# STM32H573 register map
File version: 0.4
CPU: CM33 r0p0, little endian, MPU, FPU, 4 interrupt priority bits
Registers are 32-bit, read-write, reset 0x0 unless marked. A register's access mark holds for its fields unless they carry their own. Offsets are from the block's base; [hi:lo] are bit positions; {n}, {i} and the like mark numbered series.

## TIM15 — TIM15 address block description
Base 0x40014000
Same registers: SEC_TIM15 0x50014000
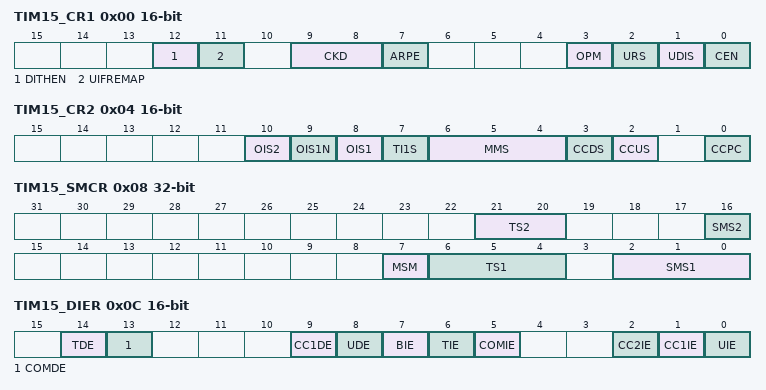
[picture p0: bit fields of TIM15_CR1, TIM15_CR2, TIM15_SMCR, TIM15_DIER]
0x00 TIM15_CR1 16-bit — TIM15 control register 1
  [12] DITHEN — Dithering enable Note: The DITHEN bit can only be modified when CEN bit is reset.
  [11] UIFREMAP — UIF status bit remapping
  [9:8] CKD — Clock division This bitfield indicates the division ratio between the timer clock (tim_ker_ck) frequency and the dead-time and sampling clock (tDTS) used by the dead-time generators and the digital filters (tim_tix)
  [7] ARPE — Auto-reload preload enable
  [3] OPM — One-pulse mode
  [2] URS — Update request source This bit is set and cleared by software to select the UEV event sources. Counter overflow/underflow Setting the UG bit Update generation through the slave mode controller
  [1] UDIS — Update disable This bit is set and cleared by software to enable/disable UEV event generation. Counter overflow/underflow Setting the UG bit Update generation through the slave mode controller Buffered registers are then loaded with their preload values.
  [0] CEN — Counter enable Note: External clock and gated mode can work only if the CEN bit has been previously set by software. However trigger mode can set the CEN bit automatically by hardware.
0x04 TIM15_CR2 16-bit — TIM15 control register 2
  [10] OIS2 — Output idle state 2 (tim_oc2 output) Note: This bit cannot be modified as long as LOCK level 1, 2 or 3 has been programmed (LOCK bits in the TIM15_BKR register).
  [9] OIS1N — Output Idle state 1 (tim_oc1n output) Note: This bit can not be modified as long as LOCK level 1, 2 or 3 has been programmed (LOCK bits in TIM15_BKR register).
  [8] OIS1 — Output Idle state 1 (tim_oc1 output) Note: This bit can not be modified as long as LOCK level 1, 2 or 3 has been programmed (LOCK bits in TIM15_BKR register).
  [7] TI1S — tim_ti1 selection
  [6:4] MMS — Master mode selection These bits allow to select the information to be sent in master mode to slave timers for synchronization (tim_trgo). The combination is as follows:
  [3] CCDS — Capture/compare DMA selection
  [2] CCUS — Capture/compare control update selection Note: This bit acts only on channels that have a complementary output.
  [0] CCPC — Capture/compare preloaded control Note: This bit acts only on channels that have a complementary output.
0x08 TIM15_SMCR — TIM15 slave mode control register
  [21:20] TS2 — Trigger selection This bit field selects the trigger input to be used to synchronize the counter. Others: Reserved See for more details on tim_itrx meaning for each timer. Note: These bits must be changed only when they are not used (e.g. when SMS=000) to avoid wrong edge detections at the transition.
  [16] SMS2 — Slave mode selection When external signals are selected the active edge of the trigger signal (tim_trgi) is linked to the polarity selected on the external input (see Input Control register and Control Register description. Others: Reserved. Note: The gated mode must not be used if tim_ti1f_ed is selected as the trigger input (TS=’00100’). Indeed, tim_ti1f_ed outputs 1 pulse for each transition on tim_ti1f, whereas the gated mode checks the level of the trigger signal. Note: The clock of the slave peripherals (timer, ADC, ...) receiving the tim_trgo signal must be enabled prior to receive events from the master timer, and the clock frequency (prescaler) must not be changed on-the-fly while triggers are received from the master timer.
  [7] MSM — Master/slave mode
  [6:4] TS1 — Trigger selection This bit field selects the trigger input to be used to synchronize the counter. Others: Reserved See for more details on tim_itrx meaning for each timer. Note: These bits must be changed only when they are not used (e.g. when SMS=000) to avoid wrong edge detections at the transition.
  [2:0] SMS1 — Slave mode selection When external signals are selected the active edge of the trigger signal (tim_trgi) is linked to the polarity selected on the external input (see Input Control register and Control Register description. Others: Reserved. Note: The gated mode must not be used if tim_ti1f_ed is selected as the trigger input (TS=’00100’). Indeed, tim_ti1f_ed outputs 1 pulse for each transition on tim_ti1f, whereas the gated mode checks the level of the trigger signal. Note: The clock of the slave peripherals (timer, ADC, ...) receiving the tim_trgo signal must be enabled prior to receive events from the master timer, and the clock frequency (prescaler) must not be changed on-the-fly while triggers are received from the master timer.
0x0C TIM15_DIER 16-bit — TIM15 DMA/interrupt enable register
  [14] TDE — Trigger DMA request enable
  [13] COMDE — COM DMA request enable
  [9] CC1DE — Capture/Compare 1 DMA request enable
  [8] UDE — Update DMA request enable
  [7] BIE — Break interrupt enable
  [6] TIE — Trigger interrupt enable
  [5] COMIE — COM interrupt enable
  [2] CC2IE — Capture/Compare 2 interrupt enable
  [1] CC1IE — Capture/Compare 1 interrupt enable
  [0] UIE — Update interrupt enable
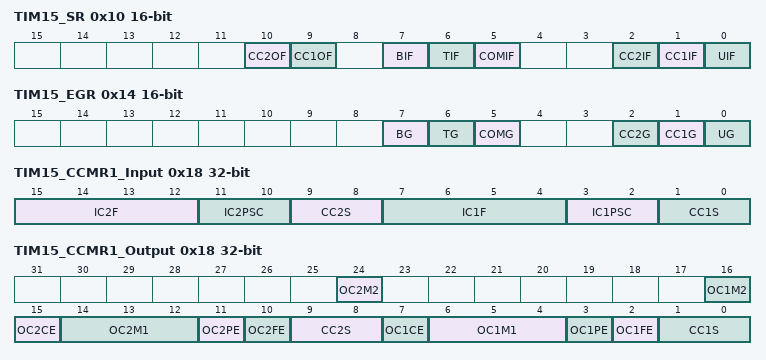
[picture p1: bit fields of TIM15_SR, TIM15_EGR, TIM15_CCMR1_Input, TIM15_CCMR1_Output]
0x10 TIM15_SR 16-bit — TIM15 status register
  [10] CC2OF — Capture/Compare 2 overcapture flag Refer to CC1OF description
  [9] CC1OF — Capture/Compare 1 overcapture flag This flag is set by hardware only when the corresponding channel is configured in input capture mode. It is cleared by software by writing it to ‘0’.
  [7] BIF — Break interrupt flag This flag is set by hardware as soon as the break input goes active. It can be cleared by software if the break input is not active.
  [6] TIF — Trigger interrupt flag This flag is set by hardware on the TRG trigger event (active edge detected on tim_trgi input when the slave mode controller is enabled in all modes but gated mode, both edges in case gated mode is selected). It is set when the counter starts or stops when gated mode is selected. It is cleared by software.
  [5] COMIF — COM interrupt flag This flag is set by hardware on a COM event (once the capture/compare control bits –CCxE, CCxNE, OCxM– have been updated). It is cleared by software.
  [2] CC2IF — Capture/Compare 2 interrupt flag refer to CC1IF description
  [1] CC1IF — Capture/Compare 1 interrupt flag This flag is set by hardware. It is cleared by software (input capture or output compare mode) or by reading the TIMx_CCR1 register (input capture mode only). If channel CC1 is configured as output: this flag is set when the content of the counter TIMx_CNT matches the content of the TIMx_CCR1 register. When the content of TIMx_CCR1 is greater than the content of TIMx_ARR, the CC1IF bit goes high on the counter overflow (in up-counting and up/down-counting modes) or underflow (in downcounting mode). There are 3 possible options for flag setting in center-aligned mode, refer to the CMS bits in the TIMx_CR1 register for the full description. If channel CC1 is configured as input: this bit is set when counter value has been captured in TIMx_CCR1 register (an edge has been detected on IC1, as per the edge sensitivity defined with the CC1P and CC1NP bits setting, in TIMx_CCER).
  [0] UIF — Update interrupt flag This bit is set by hardware on an update event. It is cleared by software. At overflow regarding the repetition counter value (update if repetition counter = 0) and if the UDIS=0 in the TIM15_CR1 register. When CNT is reinitialized by software using the UG bit in TIM15_EGR register, if URS=0 and UDIS=0 in the TIM15_CR1 register. When CNT is reinitialized by a trigger event (refer to control register (TIM15_SMCR)), if URS=0 and UDIS=0 in the TIM15_CR1 register.
0x14 TIM15_EGR 16-bit access per field — TIM15 event generation register
  [7] BG wo — Break generation This bit is set by software in order to generate an event, it is automatically cleared by hardware.
  [6] TG wo — Trigger generation This bit is set by software in order to generate an event, it is automatically cleared by hardware.
  [5] COMG rw — Capture/Compare control update generation This bit can be set by software, it is automatically cleared by hardware. Note: This bit acts only on channels that have a complementary output.
  [2] CC2G wo — Capture/Compare 2 generation Refer to CC1G description
  [1] CC1G wo — Capture/Compare 1 generation This bit is set by software in order to generate an event, it is automatically cleared by hardware. 1 A capture/compare event is generated on channel 1: If channel CC1 is configured as output: CC1IF flag is set, Corresponding interrupt or DMA request is sent if enabled. If channel CC1 is configured as input: The current value of the counter is captured in TIM15_CCR1 register. The CC1IF flag is set, the corresponding interrupt or DMA request is sent if enabled. The CC1OF flag is set if the CC1IF flag was already high.
  [0] UG wo — Update generation This bit can be set by software, it is automatically cleared by hardware.
0x18 TIM15_CCMR1_Input — TIM15 capture/compare mode register 1 [alternate]
  [15:12] IC2F — Input capture 2 filter
  [11:10] IC2PSC — Input capture 2 prescaler
  [9:8] CC2S — Capture/Compare 2 selection This bit-field defines the direction of the channel (input/output) as well as the used input. Note: CC2S bits are writable only when the channel is OFF (CC2E = ‘0’ in TIM15_CCER).
  [7:4] IC1F — Input capture 1 filter This bit-field defines the frequency used to sample tim_ti1 input and the length of the digital filter applied to tim_ti1. The digital filter is made of an event counter in which N consecutive events are needed to validate a transition on the output:
  [3:2] IC1PSC — Input capture 1 prescaler This bit-field defines the ratio of the prescaler acting on CC1 input (tim_ic1). The prescaler is reset as soon as CC1E=’0’ (TIM15_CCER register).
  [1:0] CC1S — Capture/Compare 1 selection This bit-field defines the direction of the channel (input/output) as well as the used input. Note: CC1S bits are writable only when the channel is OFF (CC1E = ‘0’ in TIM15_CCER).
0x18 TIM15_CCMR1_Output (alternate view of TIM15_CCMR1_Input) — TIM15 capture/compare mode register 1 [alternate]
  [24] OC2M2 — Output compare 2 mode
  [16] OC1M2 — Output compare 1 mode These bits define the behavior of the output reference signal tim_oc1ref from which tim_oc1 and tim_oc1n are derived. tim_oc1ref is active high whereas tim_oc1 and tim_oc1n active level depends on CC1P and CC1NP bits. Note: These bits can not be modified as long as LOCK level 3 has been programmed (LOCK bits in TIM15_BDTR register) and CC1S=’00’ (the channel is configured in output). In PWM mode, the tim_ocxref level changes only when the result of the comparison changes or when the output compare mode switches from “frozen” mode to “PWM” mode. On channels that have a complementary output, this bit field is preloaded. If the CCPC bit is set in the TIM15_CR2 register then the OC1M active bits take the new value from the preloaded bits only when a COM event is generated.
  [15] OC2CE — Output compare 2 clear enable
  [14:12] OC2M1 — Output compare 2 mode
  [11] OC2PE — Output compare 2 preload enable
  [10] OC2FE — Output compare 2 fast enable
  [9:8] CC2S — Capture/Compare 2 selection This bit-field defines the direction of the channel (input/output) as well as the used input. Note: CC2S bits are writable only when the channel is OFF (CC2E = ‘0’ in TIM15_CCER).
  [7] OC1CE — Output compare 1 clear enable
  [6:4] OC1M1 — Output compare 1 mode These bits define the behavior of the output reference signal tim_oc1ref from which tim_oc1 and tim_oc1n are derived. tim_oc1ref is active high whereas tim_oc1 and tim_oc1n active level depends on CC1P and CC1NP bits. Note: These bits can not be modified as long as LOCK level 3 has been programmed (LOCK bits in TIM15_BDTR register) and CC1S=’00’ (the channel is configured in output). In PWM mode, the tim_ocxref level changes only when the result of the comparison changes or when the output compare mode switches from “frozen” mode to “PWM” mode. On channels that have a complementary output, this bit field is preloaded. If the CCPC bit is set in the TIM15_CR2 register then the OC1M active bits take the new value from the preloaded bits only when a COM event is generated.
  [3] OC1PE — Output Compare 1 preload enable Note: These bits can not be modified as long as LOCK level 3 has been programmed (LOCK bits in TIM15_BDTR register) and CC1S=’00’ (the channel is configured in output). The PWM mode can be used without validating the preload register only in one pulse mode (OPM bit set in TIM15_CR1 register). Else the behavior is not guaranteed.
  [2] OC1FE — Output Compare 1 fast enable This bit decreases the latency between a trigger event and a transition on the timer output. It must be used in one-pulse mode (OPM bit set in TIMx_CR1 register), to have the output pulse starting as soon as possible after the starting trigger.
  [1:0] CC1S — Capture/Compare 1 selection This bit-field defines the direction of the channel (input/output) as well as the used input. Note: CC1S bits are writable only when the channel is OFF (CC1E = ‘0’ in TIM15_CCER).
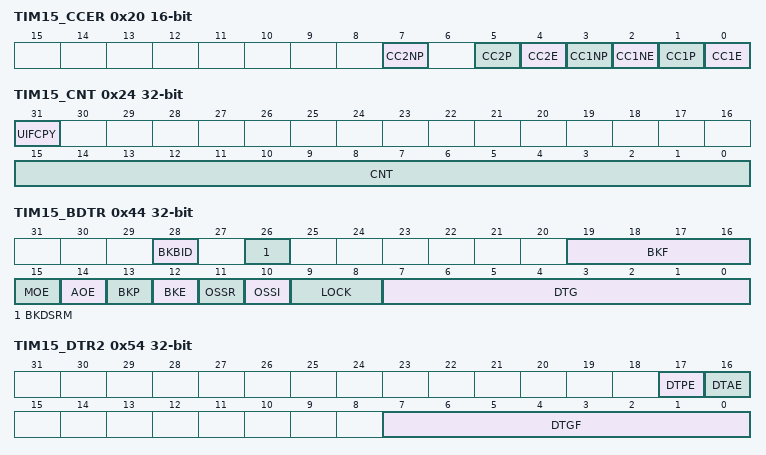
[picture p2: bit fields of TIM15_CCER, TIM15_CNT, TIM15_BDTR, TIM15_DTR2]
0x20 TIM15_CCER 16-bit — TIM15 capture/compare enable register
  [7] CC2NP — Capture/Compare 2 complementary output polarity Refer to CC1NP description
  [5] CC2P — Capture/Compare 2 output polarity Refer to CC1P description
  [4] CC2E — Capture/Compare 2 output enable Refer to CC1E description
  [3] CC1NP — Capture/Compare 1 complementary output polarity CC1 channel configured as output: CC1 channel configured as input: This bit is used in conjunction with CC1P to define the polarity of tim_ti1fp1 and tim_ti2fp1. Refer to CC1P description. Note: This bit is not writable as soon as LOCK level 2 or 3 has been programmed (LOCK bits in TIM15_BDTR register) and CC1S=”00” (the channel is configured in output). On channels that have a complementary output, this bit is preloaded. If the CCPC bit is set in the TIM15_CR2 register then the CC1NP active bit takes the new value from the preloaded bit only when a Commutation event is generated.
  [2] CC1NE — Capture/Compare 1 complementary output enable
  [1] CC1P — Capture/Compare 1 output polarity CC1 channel configured as output: When CC1 channel is configured as input, both CC1NP/CC1P bits select the active polarity of TI1FP1 and TI2FP1 for trigger or capture operations. CC1NP=0, CC1P=0: non-inverted/rising edge. The circuit is sensitive to TIxFP1 rising edge (capture or trigger operations in reset, external clock or trigger mode), TIxFP1 is not inverted (trigger operation in gated mode or encoder mode). CC1NP=0, CC1P=1: inverted/falling edge. The circuit is sensitive to TIxFP1 falling edge (capture or trigger operations in reset, external clock or trigger mode), TIxFP1 is inverted (trigger operation in gated mode or encoder mode). CC1NP=1, CC1P=1: non-inverted/both edges/ The circuit is sensitive to both TIxFP1 rising and falling edges (capture or trigger operations in reset, external clock or trigger mode), TIxFP1is not inverted (trigger operation in gated mode). This configuration must not be used in encoder mode. CC1NP=1, CC1P=0: this configuration is reserved, it must not be used. Note: This bit is not writable as soon as LOCK level 2 or 3 has been programmed (LOCK bits in TIM15_BDTR register). On channels that have a complementary output, this bit is preloaded. If the CCPC bit is set in the TIM15_CR2 register then the CC1P active bit takes the new value from the preloaded bit only when a Commutation event is generated.
  [0] CC1E — Capture/Compare 1 output enable When CC1 channel is configured as output, the OC1 level depends on MOE, OSSI, OSSR, OIS1, OIS1N and CC1NE bits, regardless of the CC1E bits state. Refer to for details.
0x24 TIM15_CNT access per field — TIM15 counter
  [31] UIFCPY ro — UIF Copy This bit is a read-only copy of the UIF bit in the TIM15_ISR register.
  [15:0] CNT rw — Counter value Non-dithering mode (DITHEN = 0) The register holds the counter value. Dithering mode (DITHEN = 1) The register only holds the non-dithered part in CNT[15:0]. The fractional part is not available.
0x28 TIM15_PSC 16-bit — TIM15 prescaler
  [15:0] PSC — Prescaler value The counter clock frequency (ftim_cnt_ck) is equal to ftim_psc_ck / (PSC[15:0] + 1). PSC contains the value to be loaded in the active prescaler register at each update event (including when the counter is cleared through UG bit of TIM15_EGR register or through trigger controller when configured in “reset mode”).
0x2C TIM15_ARR reset 0xFFFF — TIM15 auto-reload register
  [19:0] ARR — Auto-reload value ARR is the value to be loaded in the actual auto-reload register. Refer to the for more details about ARR update and behavior. The counter is blocked while the auto-reload value is null. Non-dithering mode (DITHEN = 0) The register holds the auto-reload value in ARR[15:0]. The ARR[19:16] bits are reset. Dithering mode (DITHEN = 1) The register holds the integer part in ARR[19:4]. The ARR[3:0] bitfield contains the dithered part.
0x30 TIM15_RCR 16-bit — TIM15 repetition counter register
  [7:0] REP — Repetition counter reload value This bitfield defines the update rate of the compare registers (i.e. periodic transfers from preload to active registers) when preload registers are enable. It also defines the update interrupt generation rate, if this interrupt is enable. When the repetition down-counter reaches zero, an update event is generated and it restarts counting from REP value. As the reptition counter is reloaded with REP value only at the repetition update event UEV, any write to the TIM15_RCR register is not taken in account until the next repetition update event. It means in PWM mode (REP+1) corresponds to the number of PWM periods in edge-aligned mode: the number of PWM periods in edge-aligned mode the number of half PWM period in center-aligned mode
0x34 TIM15_CCR1 — TIM15 capture/compare register 1
  [19:0] CCR1 — Capture/compare 1 value If channel CC1 is configured as output: CCR1 is the value to be loaded in the actual capture/compare 1 register (preload value). It is loaded permanently if the preload feature is not selected in the TIM15_CCMR1 register (bit OC1PE). Else the preload value is copied in the active capture/compare 1 register when an update event occurs. The active capture/compare register contains the value to be compared to the counter TIM15_CNT and signaled on tim_oc1 output. Non-dithering mode (DITHEN = 0) The register holds the compare value in CCR1[15:0]. The CCR1[19:16] bits are reset. Dithering mode (DITHEN = 1) The register holds the integer part in CCR1[19:4]. The CCR1[3:0] bitfield contains the dithered part. If channel CC1 is configured as input: CR1 is the counter value transferred by the last input capture 1 event (tim_ic1). The TIMx_CCR1 register is read-only and cannot be programmed. Non-dithering mode (DITHEN = 0) The register holds the capture value in CCR1[15:0]. The CCR1[19:16] bits are reset. Dithering mode (DITHEN = 1) The register holds the capture in CCR1[19:4]. The CCR1[3:0] bits are reset.
0x38 TIM15_CCR2 — TIM15 capture/compare register 2
  [19:0] CCR2 — Capture/compare 2 value If channel CC2 is configured as output: CCR2 is the value to be loaded in the actual capture/compare 2 register (preload value). It is loaded permanently if the preload feature is not selected in the TIM15_CCMR2 register (bit OC2PE). Else the preload value is copied in the active capture/compare 2 register when an update event occurs. The active capture/compare register contains the value to be compared to the counter TIM15_CNT and signalled on tim_oc2 output. Non-dithering mode (DITHEN = 0) The register holds the compare value in CCR2[15:0]. The CCR2[19:16] bits are reset. Dithering mode (DITHEN = 1) The register holds the integer part in CCR2[19:4]. The CCR2[3:0] bitfield contains the dithered part. If channel CC2 is configured as input: CCR2 is the counter value transferred by the last input capture 1 event (tim_ic2). The TIMx_CCR2 register is read-only and cannot be programmed. Non-dithering mode (DITHEN = 0) The register holds the capture value in CCR2[15:0]. The CCR2[19:16] bits are reset. Dithering mode (DITHEN = 1) The register holds the capture in CCR2[19:4]. The CCR2[3:0] bits are reset.
0x44 TIM15_BDTR — TIM15 break and dead-time register
  [28] BKBID — Break bidirectional In the bidirectional mode (BKBID bit set to 1), the break input is configured both in input mode and in open drain output mode. Any active break event asserts a low logic level on the Break input to indicate an internal break event to external devices. Note: This bit cannot be modified as long as LOCK level 1 has been programmed (LOCK bits in TIM15_BDTR register). Note: Any write operation to this bit takes a delay of 1 APB clock cycle to become effective.
  [26] BKDSRM — Break disarm This bit is cleared by hardware when no break source is active. The BKDSRM bit must be set by software to release the bidirectional output control (open-drain output in Hi-Z state) and then be polled until it is reset by hardware, indicating that the fault condition has disappeared. Note: Any write operation to this bit takes a delay of 1 APB clock cycle to become effective.
  [19:16] BKF — Break filter This bit-field defines the frequency used to sample the tim_brk input signal and the length of the digital filter applied to tim_brk. The digital filter is made of an event counter in which N events are needed to validate a transition on the output: Note: This bit cannot be modified when LOCK level 1 has been programmed (LOCK bits in TIM15_BDTR register).
  [15] MOE — Main output enable This bit is cleared asynchronously by hardware as soon as the tim_brk input is active. It is set by software or automatically depending on the AOE bit. It is acting only on the channels which are configured in output. See tim_ocx/tim_ocxn enable description for more details (capture/compare enable register (TIM15_CCER) on page 1985).
  [14] AOE — Automatic output enable Note: This bit can not be modified as long as LOCK level 1 has been programmed (LOCK bits in TIM15_BDTR register).
  [13] BKP — Break polarity Note: This bit can not be modified as long as LOCK level 1 has been programmed (LOCK bits in TIM15_BDTR register). Any write operation to this bit takes a delay of 1 APB clock cycle to become effective.
  [12] BKE — Break enable 1; Break inputs (tim_brk and tim_sys_brk clock failure event) enabled This bit cannot be modified when LOCK level 1 has been programmed (LOCK bits in TIM15_BDTR register). Note: Any write operation to this bit takes a delay of 1 APB clock cycle to become effective.
  [11] OSSR — Off-state selection for Run mode This bit is used when MOE=1 on channels that have a complementary output which are configured as outputs. OSSR is not implemented if no complementary output is implemented in the timer. See tim_ocx/tim_ocxn enable description for more details (capture/compare enable register (TIM15_CCER) on page 1985). Note: This bit can not be modified as soon as the LOCK level 2 has been programmed (LOCK bits in TIM15_BDTR register).
  [10] OSSI — Off-state selection for Idle mode This bit is used when MOE=0 on channels configured as outputs. See tim_ocx/tim_ocxn enable description for more details (capture/compare enable register (TIM15_CCER) on page 1985). Note: This bit can not be modified as soon as the LOCK level 2 has been programmed (LOCK bits in TIM15_BDTR register).
  [9:8] LOCK — Lock configuration These bits offer a write protection against software errors. Note: The LOCK bits can be written only once after the reset. Once the TIM15_BDTR register has been written, their content is frozen until the next reset.
  [7:0] DTG — Dead-time generator setup This bit-field defines the duration of the dead-time inserted between the complementary outputs. DT correspond to this duration. DTG[7:5]=0xx => DT=DTG[7:0]x tdtg with tdtg=tDTS DTG[7:5]=10x => DT=(64+DTG[5:0])xtdtg with Tdtg=2xtDTS DTG[7:5]=110 => DT=(32+DTG[4:0])xtdtg with Tdtg=8xtDTS DTG[7:5]=111 => DT=(32+DTG[4:0])xtdtg with Tdtg=16xtDTS Example if TDTS=125ns (8MHz), dead-time possible values are: 0 to 15875 ns by 125 ns steps, 16 �s to 31750 ns by 250 ns steps, 32 �s to 63 �s by 1 �s steps, 64 �s to 126 �s by 2 �s steps Note: This bit-field can not be modified as long as LOCK level 1, 2 or 3 has been programmed (LOCK bits in TIM15_BDTR register).
0x54 TIM15_DTR2 — TIM15 timer deadtime register 2
  [17] DTPE — Deadtime preload enable Note: This bit can not be modified as long as LOCK level 1, 2 or 3 has been programmed (LOCK bits in TIM15_BDTR register).
  [16] DTAE — Deadtime asymmetric enable Note: This bit can not be modified as long as LOCK level 1, 2 or 3 has been programmed (LOCK bits in TIM15_BDTR register).
  [7:0] DTGF — Dead-time falling edge generator setup This bit-field defines the duration of the dead-time inserted between the complementary outputs, on the falling edge. DTGF[7:5]=0xx => DTF=DTGF[7:0]x tdtg with tdtg=tDTS. DTGF[7:5]=10x => DTF=(64+DTGF[5:0])xtdtg with Tdtg=2xtDTS. DTGF[7:5]=110 => DTF=(32+DTGF[4:0])xtdtg with Tdtg=8xtDTS. DTGF[7:5]=111 => DTF=(32+DTGF[4:0])xtdtg with Tdtg=16xtDTS. Example if TDTS=125ns (8MHz), dead-time possible values are: 0 to 15875 ns by 125 ns steps, 16 us to 31750 ns by 250 ns steps, 32 us to 63us by 1 us steps, 64 us to 126 us by 2 us steps Note: This bit-field can not be modified as long as LOCK level 1, 2 or 3 has been programmed (LOCK bits in TIM15_BDTR register).
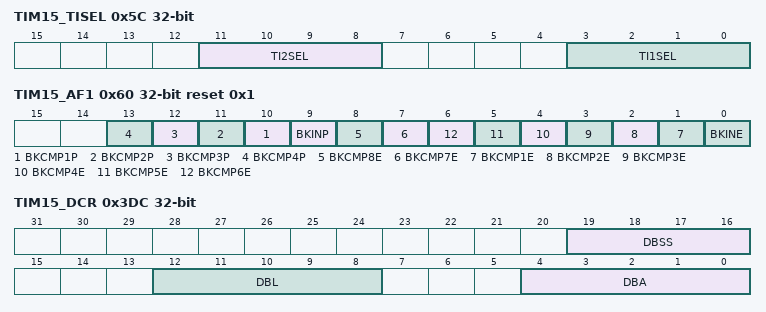
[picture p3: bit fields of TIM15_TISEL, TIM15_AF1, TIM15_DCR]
0x5C TIM15_TISEL — TIM15 input selection register
  [11:8] TI2SEL — selects tim_ti2_in[0..15] input ... Refer to for interconnects list.
  [3:0] TI1SEL — selects tim_ti1_in[0..15] input ... Refer to for interconnects list.
0x60 TIM15_AF1 reset 0x1 — TIM15 alternate function register 1
  [n+9] BKCMP{n}P (n=1..4) — tim_brk_cmp{n} input polarity This bit selects the tim_brk_cmp{n} input sensitivity. It must be programmed together with the BKP polarity bit. Note: This bit can not be modified as long as LOCK level 1 has been programmed (LOCK bits in TIM15_BDTR register).
  [9] BKINP — TIMx_BKIN input polarity This bit selects the TIMx_BKIN alternate function input sensitivity. It must be programmed together with the BKP polarity bit. Note: This bit can not be modified as long as LOCK level 1 has been programmed (LOCK bits in TIM15_BDTR register).
  [8] BKCMP8E — tim_brk_cmp8 enable This bit enables the tim_brk_cmp8 for the timer’s tim_brk input. mdf_brkx output is ‘ORed’ with the other tim_brk sources. Note: This bit can not be modified as long as LOCK level 1 has been programmed (LOCK bits in TIM15_BDTR register).
  [7] BKCMP7E — tim_brk_cmp7 enable This bit enables the tim_brk_cmp7 for the timer’s tim_brk input. COMP7 output is ‘ORed’ with the other tim_brk sources. Note: This bit can not be modified as long as LOCK level 1 has been programmed (LOCK bits in TIM15_BDTR register).
  [n] BKCMP{n}E (n=1..6) — tim_brk_cmp{n} enable This bit enables the tim_brk_cmp{n} for the timer’s tim_brk input. tim_brk_cmp{n} output is ‘ORed’ with the other tim_brk sources. Note: This bit can not be modified as long as LOCK level 1 has been programmed (LOCK bits in TIM15_BDTR register).
  [0] BKINE — TIMx_BKIN input enable This bit enables the TIMx_BKIN alternate function input for the timer’s tim_brk input. TIMx_BKIN input is ‘ORed’ with the other tim_brk sources. Note: This bit can not be modified as long as LOCK level 1 has been programmed (LOCK bits in TIM15_BDTR register).
0x64 TIM15_AF2 — TIM15 alternate function register 2
  [18:16] OCRSEL — ocref_clr source selection These bits select the ocref_clr input source. Refer to for product specific implementation. Note: These bits can not be modified as long as LOCK level 1 has been programmed (LOCK bits in TIM15_BDTR register).
0x3DC TIM15_DCR — TIM15 DMA control register
  [19:16] DBSS — DMA burst source selection This bitfield defines the interrupt source that triggers the DMA burst transfers (the timer recognizes a burst transfer when a read or a write access is done to the TIMx_DMAR address). Other: reserved
  [12:8] DBL — DMA burst length This 5-bit field defines the length of DMA transfers (the timer recognizes a burst transfer when a read or a write access is done to the TIM15_DMAR address). ...
  [4:0] DBA — DMA base address This 5-bit field defines the base-address for DMA transfers (when read/write access are done through the TIM15_DMAR address). DBA is defined as an offset starting from the address of the TIM15_CR1 register. Example: ...
0x3E0 TIM15_DMAR — TIM15 DMA address for full transfer
  [31:0] DMAB — DMA register for burst accesses A read or write operation to the DMAR register accesses the register located at the address (TIM15_CR1 address) + (DBA + DMA index) x 4 where TIM15_CR1 address is the address of the control register 1, DBA is the DMA base address configured in TIM15_DCR register, DMA index is automatically controlled by the DMA transfer, and ranges from 0 to DBL (DBL configured in TIM15_DCR).
